# IOTKit_ARMv8MBLL register map
Vendor: ARM Ltd.; Series: ARMv8-M Baseline; File version: 1.0
CPU: ARMV8MBL r0p0, little endian, MPU, no FPU, 3 interrupt priority bits, 4 SAU regions
Registers are 32-bit, read-write, reset 0x0 unless marked. A register's access mark holds for its fields unless they carry their own. Offsets are from the block's base; [hi:lo] are bit positions; 'fields as' and 'values as' point back to an identical list.

## TIMER0 — Timer 0 (Non-Secure)
Base 0x40000000
Same registers: TIMER1 0x40001000, TIMER0_Secure 0x50000000, TIMER1_Secure 0x50001000
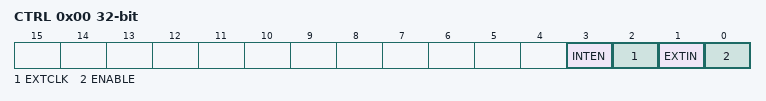
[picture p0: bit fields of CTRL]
0x00 CTRL — Control Register
  [3] INTEN — Interrupt Enable
    0=Disable (Interrupt is disabled); 1=Enable (Interrupt is enabled)
  [2] EXTCLK — External Clock Enable
    0=Disable (External Clock s disabled); 1=Enable (External Clock is enabled)
  [1] EXTIN — External Input as Enable
    0=Disable (External Input as Enable is disabled); 1=Enable (External Input as Enable is enabled)
  [0] ENABLE
    0=Disable (Timer is disabled); 1=Enable (Timer is enabled)
0x04 VALUE — Current Timer Counter Value
0x08 RELOAD — Counter Reload Value
0x0C INTSTATUS ro — Timer Interrupt status register
0x0C INTCLEAR wo write-1-clears (alternate view of INTSTATUS) — Timer Interrupt clear register

## DUALTIMER
Base 0x40002000
Same registers: DUALTIMER_Secure 0x50002000
0x00 TIMER1LOAD
0x04 TIMER1VALUE ro
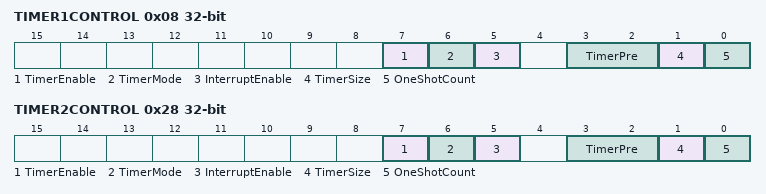
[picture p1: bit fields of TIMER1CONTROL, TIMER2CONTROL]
0x08 TIMER1CONTROL
  [7] TimerEnable — Timer Enable Enable bit.
    0=Disable (Timer is disabled.); 1=Enable (Timer is enabled.)
  [6] TimerMode — Timer Mode bit
    0=Free-Running timer mode; 1=Periodic timer mode
  [5] InterruptEnable — Interrupt Enable bit
    0=Disable (Interrupt is disabled.); 1=Enable (Interrupt is enabled.)
  [3:2] TimerPre — Timer prescale bits
    0=divided by 1 (clock is divided by 1); 1=divided by 16 (clock is divided by 16); 2=divided by 256 (clock is divided by 256)
  [1] TimerSize — Selects 16-bit or 32- bit counter operation.
    0=16-bit counter mode; 1=32-bit counter mode
  [0] OneShotCount — Selects one-shot or wrapping counter mode.
    0=Wrapping counter mode; 1=One-shot counter mode
0x0C TIMER1INTCLR wo write-1-clears — Timer 1 Interrupt Clear Register
  [0] INT — interrupt
0x10 TIMER1RIS ro — Timer 1 Raw Interrupt Status Register
  [0] RIS — Raw Timer interrupt
0x14 TIMER1MIS ro — Timer 1 Mask Interrupt Status Register
  [0] MIS — Masked Timer interrupt
0x18 TIMER1BGLOAD — Timer 1 Background Load Register
0x20 TIMER2LOAD
0x24 TIMER2VALUE ro
0x28 TIMER2CONTROL
  [7] TimerEnable — Timer Enable Enable bit.
    0=Disable (Timer is disabled.); 1=Enable (Timer is enabled.)
  [6] TimerMode — Timer Mode bit.
    0=Free-Running timer mode; 1=Periodic timer mode
  [5] InterruptEnable — Interrupt Enable bit.
    values as TIMER1CONTROL.InterruptEnable
  [3:2] TimerPre — Timer prescale bits.
    values as TIMER1CONTROL.TimerPre
  [1] TimerSize — Selects 16-bit or 32- bit counter operation.
    0=16-bit counter mode; 1=32-bit counter mode
  [0] OneShotCount — Selects one-shot or wrapping counter mode.
    0=Wrapping counter mode; 1=One-shot counter mode
0x2C TIMER2INTCLR wo write-1-clears — Timer 2 Interrupt Clear Register
  [0] INT write-1-clears — interrupt
0x30 TIMER2RIS ro — Timer 2 Raw Interrupt Status Register
  [0] RIS — Raw Timer interrupt
0x34 TIMER2MIS ro — Timer 2 Mask Interrupt Status Register
  [0] MIS — Masked Timer interrupt
0x38 TIMER2BGLOAD — Timer 2 Background Load Register

## UART0 — UART 0 (Non-Secure)
Base 0x40200000
Same registers: UART2 0x02656F10, UART1 0x40201000, UART3 0x40203000, UART4 0x40204000, UART0_Secure 0x50200000, UART1_Secure 0x50201000, UART2_Secure 0x50202000, UART3_Secure 0x50203000, UART4_Secure 0x50204000
0x00 DATA — Recieve and Transmit Data Value
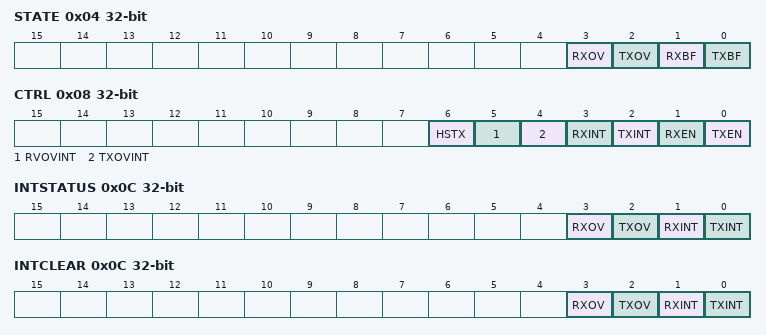
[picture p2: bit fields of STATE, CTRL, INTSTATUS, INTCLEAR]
0x04 STATE — UART Status Register
  [3] RXOV write-1-clears — RX Buffer Overun (write 1 to clear)
  [2] TXOV write-1-clears — TX Buffer Overun (write 1 to clear)
  [1] RXBF ro — RX Buffer Full
  [0] TXBF ro — TX Buffer Full
0x08 CTRL — UART Control Register
  [all] fields
    0=Disabled; 1=Enabled
  [6] HSTX — High Speed Test Mode for TX only
  [5] RVOVINT — RX Overrun Interrupt Enable
  [4] TXOVINT — TX Overrun Interrupt Enable
  [3] RXINT — RX Interrupt Enable
  [2] TXINT — TX Interrupt Enable
  [1] RXEN — RX Enable
  [0] TXEN — TX Enable
0x0C INTSTATUS ro — UART Interrupt Status Register
  [3] RXOV — RX Overrun interrupt
  [2] TXOV — TX Overrun interrupt
  [1] RXINT — RX interrupt
  [0] TXINT — TX interrupt
0x0C INTCLEAR wo (alternate view of INTSTATUS) — UART Interrupt CLEAR Register
  [3] RXOV write-1-clears — RX Overrun interrupt
  [2] TXOV write-1-clears — TX Overrun interrupt
  [1] RXINT write-1-clears — RX interrupt
  [0] TXINT write-1-clears — TX interrupt
0x10 BAUDDIV — Baudrate Divider

## Notices in the file
Copyright (C) 2012-2017 ARM Limited. All rights reserved.
Purpose: System Viewer Description (SVD) Example (Schema Version 1.1)
This is a description of a none-existent and incomplete device
for demonstration purposes only.
Redistribution and use in source and binary forms, with or without
modification, are permitted provided that the following conditions are met:
- Redistributions of source code must retain the above copyright
notice, this list of conditions and the following disclaimer.
- Redistributions in binary form must reproduce the above copyright
notice, this list of conditions and the following disclaimer in the
documentation and/or other materials provided with the distribution.
- Neither the name of ARM nor the names of its contributors may be used
to endorse or promote products derived from this software without
specific prior written permission.
THIS SOFTWARE IS PROVIDED BY THE COPYRIGHT HOLDERS AND CONTRIBUTORS "AS IS"
AND ANY EXPRESS OR IMPLIED WARRANTIES, INCLUDING, BUT NOT LIMITED TO, THE
IMPLIED WARRANTIES OF MERCHANTABILITY AND FITNESS FOR A PARTICULAR PURPOSE
ARE DISCLAIMED. IN NO EVENT SHALL COPYRIGHT HOLDERS AND CONTRIBUTORS BE
LIABLE FOR ANY DIRECT, INDIRECT, INCIDENTAL, SPECIAL, EXEMPLARY, OR
CONSEQUENTIAL DAMAGES (INCLUDING, BUT NOT LIMITED TO, PROCUREMENT OF
SUBSTITUTE GOODS OR SERVICES; LOSS OF USE, DATA, OR PROFITS; OR BUSINESS
INTERRUPTION) HOWEVER CAUSED AND ON ANY THEORY OF LIABILITY, WHETHER IN
CONTRACT, STRICT LIABILITY, OR TORT (INCLUDING NEGLIGENCE OR OTHERWISE)
ARISING IN ANY WAY OUT OF THE USE OF THIS SOFTWARE, EVEN IF ADVISED OF THE
POSSIBILITY OF SUCH DAMAGE.
